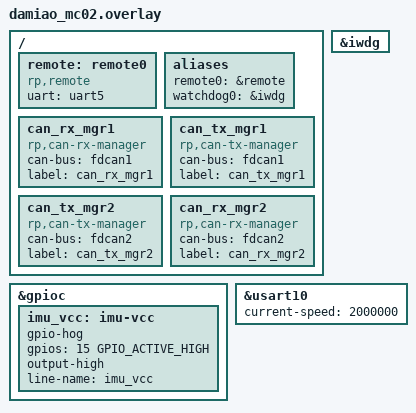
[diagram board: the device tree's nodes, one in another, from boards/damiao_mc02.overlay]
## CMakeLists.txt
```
cmake_minimum_required(VERSION 3.20)

if(NOT BOARD)
    set(BOARD damiao_mc02)
    message("BOARD not defined, use default value: ${BOARD}")
else()
    message("Use BOARD: ${BOARD}")
endif()

# 把同目录下的 algo / ramenx 注册为 Zephyr 模块（各自的 zephyr/module.yml）
# 注意：必须在 find_package(Zephyr) 之前
list(APPEND ZEPHYR_EXTRA_MODULES
    ${CMAKE_CURRENT_LIST_DIR}/algo
    ${CMAKE_CURRENT_LIST_DIR}/ramenx
    ${CMAKE_CURRENT_LIST_DIR}/breeze-modules
)

find_package(Zephyr REQUIRED HINTS $ENV{ZEPHYR_BASE})

project(breeze_template)

# 关键：app 必须与 algo 库使用一致的 ALGO_ENABLE_ARM_MATH 定义。
# 该宏决定 Matrix<float> 走 CMSIS-DSP 特化（含 armBuffer_，sizeof=1080）
# 还是纯头文件模板（sizeof=1044）。algo 库在 algo/CMakeLists.txt 里
# 通过 add_compile_definitions 定义了它，但作用域只在 algo 模块内，
# 不会传到 app。若 app 不定义，两边对 Matrix<float> 的布局理解不一致
# （ODR 违规），Ekf::Config 拷贝时偏移错位、读到垃圾 rows/cols，
# 最终触发 BUS FAULT（BFAR 通常是个非法地址）。
if(CONFIG_ALGO_ENABLE_ARM_MATH)
    target_compile_definitions(app PRIVATE ALGO_ENABLE_ARM_MATH)
endif()

# 直接添加所有源文件到 app
target_sources(app PRIVATE

    src/main.cpp
    src/TaskLayer/all_task.cpp
    src/TaskLayer/conf_task.cpp
    src/DeviceLayer/device.cpp
    src/DeviceLayer/iwdg.c
    src/DeviceLayer/rtt.c
)
# 添加头文件路径
target_include_directories(app PRIVATE
    ${CMAKE_CURRENT_LIST_DIR}/algo/include   # algo 算法库头文件（robotpilots/algorithm/*.hpp）
    src/DeviceLayer                 # 设备层头文件（如 device.hpp）
    src/TaskLayer                   # 任务层头文件（如 conf_task.hpp）
    src/ConfigLayer                 # 配置层头文件（如 rp_device_config.h）
)

target_link_libraries(app PRIVATE ramenx)
```

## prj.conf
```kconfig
# 传感器：SENSOR / BMI08X 已在板级 defconfig 默认打开，这里只开需要的 stream 模式
CONFIG_BMI08X_ACCEL_STREAM=y
CONFIG_BMI08X_GYRO_STREAM=y
# 启用遥控器驱动
# CONFIG_REMOTE=y
CONFIG_UART_ASYNC_API=y
CONFIG_DCACHE=n
# 电机（DeviceLayer/device_motor.cpp 使用）
CONFIG_CAN=y
CONFIG_BLDCM=y
# DJI 电机 CAN 通常为 1Mbps
CONFIG_CAN_DEFAULT_BITRATE=1000000
CONFIG_CAN_RX_MANAGER=y
CONFIG_CAN_TX_MANAGER=y
# 丢帧告警限流：累计每丢 100 帧才打一条，避免刷屏冲掉其它日志
CONFIG_CAN_RX_MANAGER_MSGQ_WARN_EVERY_N_DROPS=100
# DJI 心跳自动检测（shared system workqueue）
CONFIG_BLDCM_HEARTBEAT_AUTOCHECK=y
CONFIG_BLDCM_HEARTBEAT_POLL_PERIOD_MS=100
# 看门狗（IWDG_STM32 驱动默认就开）
CONFIG_WATCHDOG=y

# 启用日志：模式用默认的 DEFERRED（改回 IMMEDIATE 的话各线程栈要重新评估，见 conf_task.hpp）
CONFIG_LOG=y
CONFIG_LOG_PROCESS_THREAD_STACK_SIZE=4096
# 延迟模式环形缓冲默认只有 1KB，装不下线程分析器那一屏报告（超了直接丢）
CONFIG_LOG_BUFFER_SIZE=8192
# 每条日志立刻唤醒 log 线程输出，而不是等 1000ms 或攒够 10 条
CONFIG_LOG_PROCESS_TRIGGER_THRESHOLD=1
# 启用CMSIS-DSP库
CONFIG_CMSIS_DSP=y
# 启用 robotpilots 算法库（algo/），矩阵/KF/EKF 走 CMSIS-DSP 加速
CONFIG_ALGO=y
CONFIG_ALGO_ENABLE_ARM_MATH=y
# 启用 ramenx（ramen 消息/数据流库扩展，ramenx/），ramen 本身要求 C++20
CONFIG_RAMENX=y
# C++ 支持（ramen 使用 concepts/requires，必须 C++20；FPU_SHARING 由 FPU 自动带出）
CONFIG_STD_CPP20=y
CONFIG_FPU=y
#启用模块
CONFIG_BREEZE_MODULES=y
CONFIG_BREEZE_MODULE_SHOOTER=y

# RTT 日志后端
CONFIG_CONSOLE=y
CONFIG_USE_SEGGER_RTT=y
CONFIG_RTT_CONSOLE=y
CONFIG_SEGGER_RTT_MAX_NUM_UP_BUFFERS=5
CONFIG_SEGGER_RTT_MAX_NUM_DOWN_BUFFERS=2
# 默认 1KB 上行缓冲写满会丢消息；调大 + 满了覆盖最旧数据，不阻塞也不丢关键信息
CONFIG_SEGGER_RTT_BUFFER_SIZE_UP=8192
CONFIG_LOG_BACKEND_RTT_MODE_OVERWRITE=y
#用于调试的宏 
CONFIG_DEBUG_OPTIMIZATIONS=y
CONFIG_ASSERT=y
# 线程名：开启后线程分析器才会显示 main/idle/logging 等名字
CONFIG_THREAD_NAME=y
CONFIG_MPU_STACK_GUARD=y
CONFIG_THREAD_ANALYZER=y
CONFIG_THREAD_ANALYZER_AUTO=y
# 分析器线程走 printk，1KB 栈实测已用 984B（96%），被抢占就栈溢出 + MPU FAULT
CONFIG_THREAD_ANALYZER_AUTO_STACK_SIZE=4096
# main线程
CONFIG_MAIN_STACK_SIZE=8192
```

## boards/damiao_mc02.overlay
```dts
/* This file will automatic applyed when using damiao_mc02 board */

/ {
    remote: remote0 {
        status = "okay";
        compatible = "rp,remote";
        uart = <&uart5>;
    };
    aliases {
        remote0 = &remote;
    };

    can_rx_mgr1: can_rx_mgr1 {
        compatible = "rp,can-rx-manager";
        status = "okay";
        can-bus = <&fdcan1>;
        label = "can_rx_mgr1";
    };

    can_tx_mgr1: can_tx_mgr1 {
        compatible = "rp,can-tx-manager";
        status = "okay";
        can-bus = <&fdcan1>;
        label = "can_tx_mgr1";
    };

    can_tx_mgr2: can_tx_mgr2 {
        compatible = "rp,can-tx-manager";
        status = "okay";
        can-bus = <&fdcan2>;
        label = "can_tx_mgr2";
    };

    can_rx_mgr2: can_rx_mgr2 {
        compatible = "rp,can-rx-manager";
        status = "okay";
        can-bus = <&fdcan2>;
        label = "can_rx_mgr2";
    };

};

/ {
    aliases {
        watchdog0 = &iwdg;  /* 将 watchdog0 指向 IWDG 硬件 */
    };
};

&iwdg {
    status = "okay"; /* 启用独立看门狗 IWDG */
};


&gpioc {
	/* 板载可控电源使能：PC15 高电平开电
	 * gpio-hog：Zephyr 在 POST_KERNEL 自动把该引脚配成输出并拉高，
	 * 早于 main()，不需要任何电源管理代码。
	 */
	imu_vcc: imu-vcc {
		gpio-hog;
		gpios = <15 GPIO_ACTIVE_HIGH>;
		output-high;
		line-name = "imu_vcc";
	};
};

&usart10 {
	current-speed = <2000000>;
};
```

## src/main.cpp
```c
#include "zephyr/kernel.h"
#include "zephyr/logging/log.h"
#include <stdint.h>				// 整型类型
#include <SEGGER_RTT.h>			// RTT
#include "conf_task.hpp"
#include "device.hpp"				// 设备

LOG_MODULE_REGISTER(infantry_up_test, LOG_LEVEL_INF);


int main()
{

	if (Device_Init() != 0)
	{
		LOG_ERR("Device initialization failed, halting system.");
		// 停止系统，避免运行任务，同时输出报错地方
		k_panic(); 
	}
	breeze::InitProcess();
	while (1)
	{
		k_sleep(K_FOREVER); // 永远挂起，不消耗 CPU
		
	}
}
```
